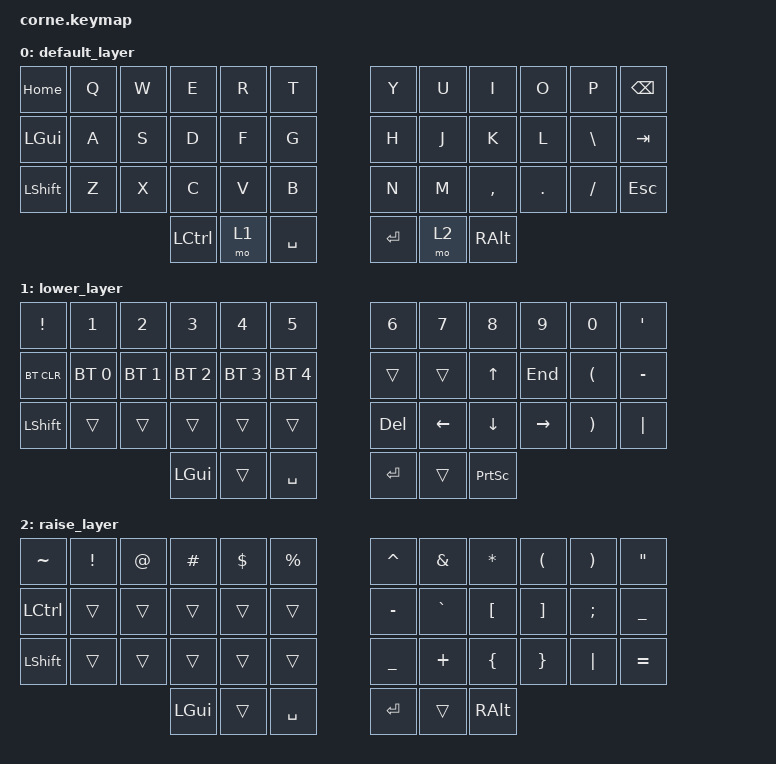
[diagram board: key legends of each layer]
#include <behaviors.dtsi>
#include <dt-bindings/zmk/keys.h>
#include <dt-bindings/zmk/bt.h>
#include <dt-bindings/zmk/rgb.h>

/ {
        keymap {
                compatible = "zmk,keymap";

                default_layer {
// -----------------------------------------------------------------------------------------
// | HOME |  Q  |  W  |  E  |  R  |  T  |   |  Y  |  U   |  I  |  O  |  P  | BSPC |
// | GUI |  A  |  S  |  D  |  F  |  G  |   |  H  |  J   |  K  |  L  |  \  | TAB  |
// | SHFT |  Z  |  X  |  C  |  V  |  B  |   |  N  |  M   |  ,  |  .  |  /  | ESC  |
//                    | CTRL | LWR | SPC |   | ENT | RSE  | ALT |
                        bindings = <
   &kp HOME &kp Q &kp W &kp E &kp R &kp T   &kp Y &kp U  &kp I     &kp O   &kp P    &kp BSPC
   &kp LGUI &kp A &kp S &kp D &kp F &kp G &kp H &kp J &kp K &kp L   &kp BSLH &kp TAB
   &kp LSHFT &kp Z &kp X &kp C &kp V &kp B   &kp N &kp M  &kp COMMA &kp DOT &kp FSLH &kp ESC
                  &kp LCTRL &mo 1 &kp SPACE   &kp RET &mo 2 &kp RALT
                        >;
                };
                lower_layer {
// -----------------------------------------------------------------------------------------
// |  !   |  1  |  2  |  3  |  4  |  5  |   |  6  |  7  |  8  |  9  |  0   |  '  |
// | BTCLR| BT1 | BT2 | BT3 | BT4 | BT5 |   |     |     |  UP | END |  (   |  -  |
// | SHFT |     |     |     |     |     |   | DEL | LFT | DWN | RGT |  )   | "|" |
//                    | GUI |     | SPC |   | ENT |     | PSCRN |
                        bindings = <
   &kp EXCL   &kp N1       &kp N2       &kp N3       &kp N4       &kp N5        &kp N6   &kp N7    &kp N8   &kp N9    &kp N0 &kp SQT
   &bt BT_CLR &bt BT_SEL 0 &bt BT_SEL 1 &bt BT_SEL 2 &bt BT_SEL 3 &bt BT_SEL 4  &trans   &trans    &kp UP   &kp END   &kp LPAR &kp MINUS
   &kp LSHFT  &trans       &trans       &trans       &trans       &trans        &kp DEL  &kp LEFT  &kp DOWN &kp RIGHT &kp RPAR &kp PIPE
                                    &kp LGUI     &trans       &kp SPACE         &kp RET  &trans    &kp PSCRN
                        >;
                };

                raise_layer {
// -----------------------------------------------------------------------------------------
// |  ~ |  !  |  @  |  #  |  $  |  %  |   |  ^  |  &  |  *  |  (  |  )    |  ""  |
// | CTRL |     |     |     |     |     |   |  -  |     |  [  |  ]  |  ;  |  _  |
// | SHFT |     |     |     |     |     |   |  _  |  +  |  {  |  }  | "|" |  =  |
//                    | GUI |     | SPC |   | ENT |     | ALT |
                        bindings = <
   &kp  TILDE  &kp EXCL &kp AT &kp HASH &kp DLLR &kp PRCNT   &kp CARET &kp AMPS  &kp ASTRK &kp LPAR &kp RPAR &kp DQT
   &kp LCTRL &trans   &trans &trans   &trans   &trans      &kp MINUS &kp GRAVE &kp LBKT  &kp RBKT &kp SEMI &kp UNDER
   &kp LSHFT &trans   &trans &trans   &trans   &trans      &kp UNDER &kp PLUS  &kp LBRC  &kp RBRC &kp PIPE&kp EQUAL
                             &kp LGUI &trans   &kp SPACE   &kp RET   &trans    &kp RALT
                        >;
                };
        };
};
